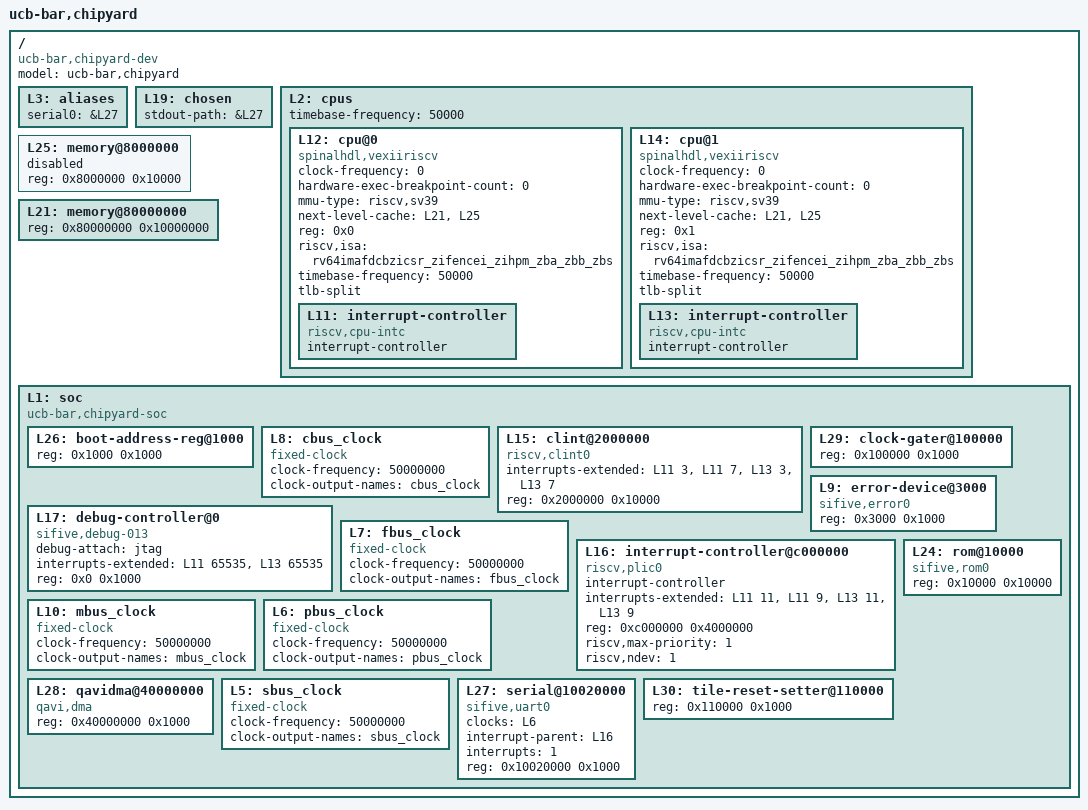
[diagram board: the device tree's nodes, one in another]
/dts-v1/;

/ {
	#address-cells = <1>;
	#size-cells = <1>;
	compatible = "ucb-bar,chipyard-dev";
	model = "ucb-bar,chipyard";
	L3: aliases {
		serial0 = &L27;
	};
	L19: chosen {
		stdout-path = &L27;
	};
	L2: cpus {
		#address-cells = <1>;
		#size-cells = <0>;
		timebase-frequency = <50000>;
		L12: cpu@0 {
			clock-frequency = <0>;
			compatible = "spinalhdl,vexiiriscv", "riscv";
			device_type = "cpu";
			hardware-exec-breakpoint-count = <0>;
			mmu-type = "riscv,sv39";
			next-level-cache = <&L21 &L25>;
			reg = <0x0>;
			riscv,isa = "rv64imafdcbzicsr_zifencei_zihpm_zba_zbb_zbs";
			status = "okay";
			timebase-frequency = <50000>;
			tlb-split;
			L11: interrupt-controller {
				#interrupt-cells = <1>;
				compatible = "riscv,cpu-intc";
				interrupt-controller;
			};
		};
		L14: cpu@1 {
			clock-frequency = <0>;
			compatible = "spinalhdl,vexiiriscv", "riscv";
			device_type = "cpu";
			hardware-exec-breakpoint-count = <0>;
			mmu-type = "riscv,sv39";
			next-level-cache = <&L21 &L25>;
			reg = <0x1>;
			riscv,isa = "rv64imafdcbzicsr_zifencei_zihpm_zba_zbb_zbs";
			status = "okay";
			timebase-frequency = <50000>;
			tlb-split;
			L13: interrupt-controller {
				#interrupt-cells = <1>;
				compatible = "riscv,cpu-intc";
				interrupt-controller;
			};
		};
	};
	L25: memory@8000000 {
		device_type = "memory";
		reg = <0x8000000 0x10000>;
		status = "disabled";
	};
	L21: memory@80000000 {
		device_type = "memory";
		reg = <0x80000000 0x10000000>;
	};
	L1: soc {
		#address-cells = <1>;
		#size-cells = <1>;
		compatible = "ucb-bar,chipyard-soc", "simple-bus";
		ranges;
		L26: boot-address-reg@1000 {
			reg = <0x1000 0x1000>;
			reg-names = "control";
		};
		L8: cbus_clock {
			#clock-cells = <0>;
			clock-frequency = <50000000>;
			clock-output-names = "cbus_clock";
			compatible = "fixed-clock";
		};
		L15: clint@2000000 {
			compatible = "riscv,clint0";
			interrupts-extended = <&L11 3 &L11 7 &L13 3 &L13 7>;
			reg = <0x2000000 0x10000>;
			reg-names = "control";
		};
		L29: clock-gater@100000 {
			reg = <0x100000 0x1000>;
			reg-names = "control";
		};
		L17: debug-controller@0 {
			compatible = "sifive,debug-013", "riscv,debug-013";
			debug-attach = "jtag";
			interrupts-extended = <&L11 65535 &L13 65535>;
			reg = <0x0 0x1000>;
			reg-names = "control";
		};
		L9: error-device@3000 {
			compatible = "sifive,error0";
			reg = <0x3000 0x1000>;
		};
		L7: fbus_clock {
			#clock-cells = <0>;
			clock-frequency = <50000000>;
			clock-output-names = "fbus_clock";
			compatible = "fixed-clock";
		};
		L16: interrupt-controller@c000000 {
			#interrupt-cells = <1>;
			compatible = "riscv,plic0";
			interrupt-controller;
			interrupts-extended = <&L11 11 &L11 9 &L13 11 &L13 9>;
			reg = <0xc000000 0x4000000>;
			reg-names = "control";
			riscv,max-priority = <1>;
			riscv,ndev = <1>;
		};
		L10: mbus_clock {
			#clock-cells = <0>;
			clock-frequency = <50000000>;
			clock-output-names = "mbus_clock";
			compatible = "fixed-clock";
		};
		L6: pbus_clock {
			#clock-cells = <0>;
			clock-frequency = <50000000>;
			clock-output-names = "pbus_clock";
			compatible = "fixed-clock";
		};
		L28: qavidma@40000000 {
			compatible = "qavi,dma";
			reg = <0x40000000 0x1000>;
			reg-names = "control";
		};
		L24: rom@10000 {
			compatible = "sifive,rom0";
			reg = <0x10000 0x10000>;
			reg-names = "mem";
		};
		L5: sbus_clock {
			#clock-cells = <0>;
			clock-frequency = <50000000>;
			clock-output-names = "sbus_clock";
			compatible = "fixed-clock";
		};
		L27: serial@10020000 {
			clocks = <&L6>;
			compatible = "sifive,uart0";
			interrupt-parent = <&L16>;
			interrupts = <1>;
			reg = <0x10020000 0x1000>;
			reg-names = "control";
		};
		L30: tile-reset-setter@110000 {
			reg = <0x110000 0x1000>;
			reg-names = "control";
		};
	};
};
